VERSION ""

NS_ :

BS_:

BU_: Gateway RearData_Module04 FrontData_Module01 MegaSniffer_Module02 EngineDataExtra_Module03

BO_ 1796 CAN_Settings_ECU04: 8 Vector__XXX

BO_ 1795 CAN_Settings_ECU03: 8 Vector__XXX

BO_ 1794 CAN_Settings_ECU02: 8 Vector__XXX

BO_ 1793 CAN_Settings_ECU01: 8 Vector__XXX

BO_ 19 MAP: 2 MegaSniffer_Module02
 SG_ MAP : 0|10@1+ (250,0) [0|255750] "Pa"  Gateway

BO_ 18 SuspFront: 4 FrontData_Module01
 SG_ SuspFrontRight : 16|10@1+ (1,0) [0|0] ""  Gateway
 SG_ SuspFrontLeft : 0|10@1+ (0.088,0) [0|90.024] "deg"  Gateway

BO_ 17 TPS: 1 MegaSniffer_Module02
 SG_ TPS : 0|8@1+ (1,0) [0|255] "%"  Gateway

BO_ 16 WaterTemp: 1 MegaSniffer_Module02
 SG_ WaterTemp : 0|8@1+ (1,0) [0|255] "degC"  Gateway

BO_ 15 AirTemp: 1 MegaSniffer_Module02
 SG_ AirTemp : 0|8@1+ (1,0) [0|255] "degC"  Gateway

BO_ 14 Speed: 1 RearData_Module04
 SG_ Speed : 0|8@1+ (1,0) [0|255] "km/h"  Gateway

BO_ 13 OilTemp: 1 RearData_Module04
 SG_ OilTemp : 0|8@1+ (1,0) [0|255] "degC"  Gateway

BO_ 12 OilPressure: 1 RearData_Module04
 SG_ OilPressure : 0|8@1+ (0.1,0) [0|25.5] "Bar"  Gateway

BO_ 11 SuspRear: 4 RearData_Module04
 SG_ SuspRearRight : 16|10@1+ (1,0) [0|0] ""  Gateway
 SG_ SuspRearLeft : 0|10@1+ (1,0) [0|0] ""  Gateway

BO_ 10 Pressure: 8 EngineDataExtra_Module03

BO_ 9 Temperature: 8 EngineDataExtra_Module03

BO_ 8 GearPosition: 1 EngineDataExtra_Module03
 SG_ GearPosition : 0|8@1+ (1,0) [0|6] "Gear"  Gateway

BO_ 7 Lambda: 1 MegaSniffer_Module02
 SG_ Lambda : 0|8@1+ (0.01,0) [0|2.55] ""  Gateway

BO_ 0 RPM: 1 MegaSniffer_Module02
 SG_ RPM : 0|8@1+ (51,0) [0|13005] "RPM"  Gateway

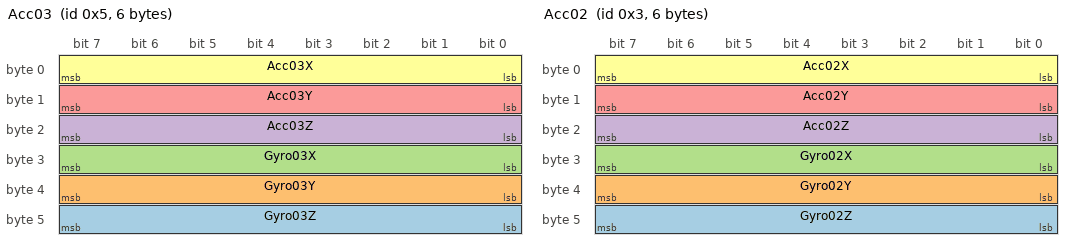
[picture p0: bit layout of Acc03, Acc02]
BO_ 5 Acc03: 6 RearData_Module04
 SG_ Gyro03Z : 40|8@1- (2,0) [-256|254] "deg/s"  Gateway
 SG_ Gyro03Y : 32|8@1- (2,0) [-256|254] "deg/s"  Gateway
 SG_ Gyro03X : 24|8@1- (2,0) [-256|254] "deg/s"  Gateway
 SG_ Acc03Z : 16|8@1- (0.008,0) [-1.024|1.016] "G"  Gateway
 SG_ Acc03Y : 8|8@1- (0.008,0) [-1.024|1.016] "G"  Gateway
 SG_ Acc03X : 0|8@1- (0.008,0) [-1.024|1.016] "G"  Gateway

BO_ 3 Acc02: 6 FrontData_Module01
 SG_ Gyro02Z : 40|8@1- (2,0) [-256|254] "deg/s"  Gateway
 SG_ Gyro02Y : 32|8@1- (2,0) [-256|254] "deg/s"  Gateway
 SG_ Gyro02X : 24|8@1- (2,0) [-256|254] "deg/s"  Gateway
 SG_ Acc02Z : 16|8@1- (0.008,0) [-1.024|1.016] "G"  Gateway
 SG_ Acc02Y : 8|8@1- (0.008,0) [-1.024|1.016] "G"  Gateway
 SG_ Acc02X : 0|8@1- (0.008,0) [-1.024|1.016] "G"  Gateway

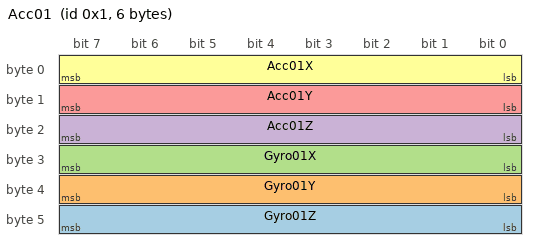
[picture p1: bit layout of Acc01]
BO_ 1 Acc01: 6 FrontData_Module01
 SG_ Gyro01Z : 40|8@1- (2,0) [-256|254] "deg/s"  Gateway
 SG_ Gyro01Y : 32|8@1- (2,0) [-256|254] "deg/s"  Gateway
 SG_ Gyro01X : 24|8@1- (2,0) [-256|254] "deg/s"  Gateway
 SG_ Acc01Z : 16|8@1- (0.008,0) [-1.024|1.016] "G"  Gateway
 SG_ Acc01Y : 8|8@1- (0.008,0) [-1.024|1.016] "G"  Gateway
 SG_ Acc01X : 0|8@1- (0.008,0) [-1.024|1.016] "G"  Gateway

BA_DEF_  "BusType" STRING ;
BA_DEF_DEF_  "BusType" "CAN";
